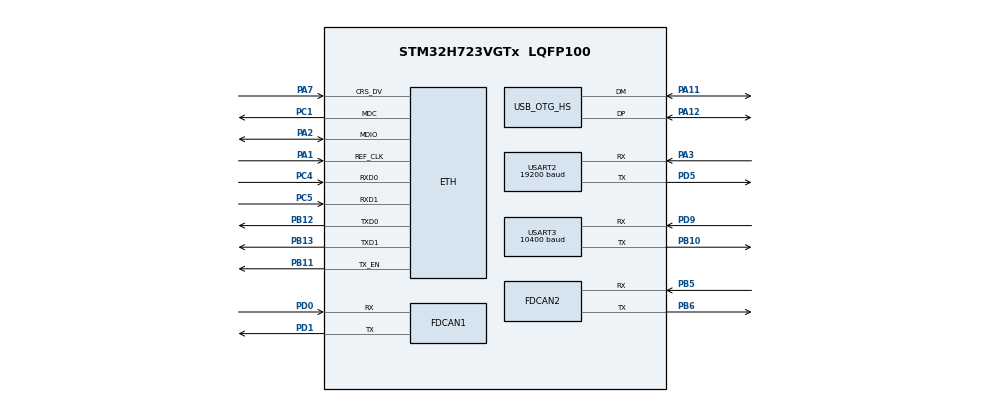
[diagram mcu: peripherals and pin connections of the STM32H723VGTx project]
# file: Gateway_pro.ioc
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CORTEX_M7.default_mode_Activation=1
Dma.Request0=USART2_RX
Dma.Request1=USART2_TX
Dma.USART2_RX.0.Direction=DMA_PERIPH_TO_MEMORY
Dma.USART2_RX.0.EventEnable=DISABLE
Dma.USART2_RX.0.FIFOMode=DMA_FIFOMODE_DISABLE
Dma.USART2_RX.0.Instance=DMA1_Stream0
Dma.USART2_RX.0.MemDataAlignment=DMA_MDATAALIGN_WORD
Dma.USART2_RX.0.MemInc=DMA_MINC_ENABLE
Dma.USART2_RX.0.Mode=DMA_CIRCULAR
Dma.USART2_RX.0.PeriphDataAlignment=DMA_PDATAALIGN_WORD
Dma.USART2_RX.0.PeriphInc=DMA_PINC_DISABLE
Dma.USART2_RX.0.Polarity=HAL_DMAMUX_REQ_GEN_RISING
Dma.USART2_RX.0.Priority=DMA_PRIORITY_LOW
Dma.USART2_RX.0.RequestNumber=1
Dma.USART2_RX.0.SignalID=NONE
Dma.USART2_RX.0.SyncEnable=DISABLE
Dma.USART2_RX.0.SyncPolarity=HAL_DMAMUX_SYNC_NO_EVENT
Dma.USART2_RX.0.SyncRequestNumber=1
Dma.USART2_RX.0.SyncSignalID=NONE
Dma.USART2_TX.1.Direction=DMA_MEMORY_TO_PERIPH
Dma.USART2_TX.1.EventEnable=DISABLE
Dma.USART2_TX.1.FIFOMode=DMA_FIFOMODE_DISABLE
Dma.USART2_TX.1.Instance=DMA1_Stream1
Dma.USART2_TX.1.MemDataAlignment=DMA_MDATAALIGN_WORD
Dma.USART2_TX.1.MemInc=DMA_MINC_ENABLE
Dma.USART2_TX.1.Mode=DMA_CIRCULAR
Dma.USART2_TX.1.PeriphDataAlignment=DMA_PDATAALIGN_WORD
Dma.USART2_TX.1.PeriphInc=DMA_PINC_DISABLE
Dma.USART2_TX.1.Polarity=HAL_DMAMUX_REQ_GEN_RISING
Dma.USART2_TX.1.Priority=DMA_PRIORITY_LOW
Dma.USART2_TX.1.RequestNumber=1
Dma.USART2_TX.1.SignalID=NONE
Dma.USART2_TX.1.SyncEnable=DISABLE
Dma.USART2_TX.1.SyncPolarity=HAL_DMAMUX_SYNC_NO_EVENT
Dma.USART2_TX.1.SyncRequestNumber=1
Dma.USART2_TX.1.SyncSignalID=NONE
ETH.MediaInterface=HAL_ETH_RMII_MODE
FDCAN1.CalculateBaudRateNominal=2604166
FDCAN1.CalculateTimeBitNominal=384
FDCAN1.CalculateTimeQuantumNominal=128.0
FDCAN2.CalculateBaudRateNominal=2604166
FDCAN2.CalculateTimeBitNominal=384
FDCAN2.CalculateTimeQuantumNominal=128.0
FREERTOS.Tasks01=defaultTask,24,128,StartDefaultTask,Default,NULL,Dynamic,NULL,NULL
FREERTOS.configENABLE_FPU=1
FREERTOS.configUSE_NEWLIB_REENTRANT=1
Mcu.Family=STM32H7
Mcu.Name=STM32H723VGTx
Mcu.Package=LQFP100
NVIC.DMA1_Stream0_IRQn=true\:5\:0\:false\:false\:true\:true\:false\:true\:true
NVIC.DMA1_Stream1_IRQn=true\:5\:0\:false\:false\:true\:true\:false\:true\:true
NVIC.OTG_HS_IRQn=true\:5\:0\:false\:false\:true\:true\:false\:true\:true
NVIC.PriorityGroup=NVIC_PRIORITYGROUP_4
NVIC.TIM6_DAC_IRQn=true\:15\:0\:false\:false\:true\:false\:false\:true\:true
NVIC.TimeBase=TIM6_DAC_IRQn
NVIC.TimeBaseIP=TIM6
PA1.Mode=RMII
PA1.Signal=ETH_REF_CLK
PA11.Mode=Device_Only_FS
PA11.Signal=USB_OTG_HS_DM
PA12.Mode=Device_Only_FS
PA12.Signal=USB_OTG_HS_DP
PA2.Mode=RMII
PA2.Signal=ETH_MDIO
PA3.Mode=Asynchronous
PA3.Signal=USART2_RX
PA7.Mode=RMII
PA7.Signal=ETH_CRS_DV
PB10.Mode=Asynchronous
PB10.Signal=USART3_TX
PB11.Mode=RMII
PB11.Signal=ETH_TX_EN
PB12.Mode=RMII
PB12.Signal=ETH_TXD0
PB13.Mode=RMII
PB13.Signal=ETH_TXD1
PB5.Mode=FDCAN_Activate
PB5.Signal=FDCAN2_RX
PB6.Mode=FDCAN_Activate
PB6.Signal=FDCAN2_TX
PC1.Mode=RMII
PC1.Signal=ETH_MDC
PC4.Mode=RMII
PC4.Signal=ETH_RXD0
PC5.Mode=RMII
PC5.Signal=ETH_RXD1
PD0.Mode=FDCAN_Activate
PD0.Signal=FDCAN1_RX
PD1.Mode=FDCAN_Activate
PD1.Signal=FDCAN1_TX
PD5.Mode=Asynchronous
PD5.Signal=USART2_TX
PD9.Mode=Asynchronous
PD9.Signal=USART3_RX
PH0-OSC_IN.Mode=HSE-External-Oscillator
PH0-OSC_IN.Signal=RCC_OSC_IN
PH1-OSC_OUT.Mode=HSE-External-Oscillator
PH1-OSC_OUT.Signal=RCC_OSC_OUT
ProjectManager.HeapSize=0x200
ProjectManager.StackSize=0x400
ProjectManager.TargetToolchain=STM32CubeIDE
RCC.ADCFreq_Value=50390625
RCC.APB1Freq_Value=125000000
RCC.APB2Freq_Value=125000000
RCC.APB3Freq_Value=125000000
RCC.APB4Freq_Value=125000000
RCC.CortexFreq_Value=500000000
RCC.D1PPRE=RCC_APB3_DIV2
RCC.D2PPRE1=RCC_APB1_DIV2
RCC.D2PPRE2=RCC_APB2_DIV2
RCC.D3PPRE=RCC_APB4_DIV2
RCC.DIVM1=2
RCC.DIVN1=40
RCC.DIVP1=1
RCC.DIVQ1=4
RCC.HCLKFreq_Value=250000000
RCC.HPRE=RCC_HCLK_DIV2
RCC.PLLFRACN=0
RCC.SYSCLKFreq_VALUE=500000000
RCC.SYSCLKSource=RCC_SYSCLKSOURCE_PLLCLK
RCC.USBFreq_Value=125000000
TIM2.Prescaler=249
USART2.BaudRate=19200
USART2.VirtualMode-Asynchronous=VM_ASYNC
USART3.BaudRate=10400
USART3.VirtualMode-Asynchronous=VM_ASYNC
USB_DEVICE.CLASS_NAME_HS=CDC
USB_DEVICE.VirtualMode=Cdc
USB_DEVICE.VirtualModeHS=Cdc_HS
USB_OTG_HS.VirtualMode-Device_Only_FS=Device_Only_FS
VP_FREERTOS_VS_CMSIS_V2.Mode=CMSIS_V2
VP_MEMORYMAP_VS_MEMORYMAP.Mode=CurAppReg
VP_RNG_VS_RNG.Mode=RNG_Activate
VP_SYS_VS_tim6.Mode=TIM6
VP_TIM2_VS_ClockSourceINT.Mode=Internal
VP_USB_DEVICE_VS_USB_DEVICE_CDC_HS.Mode=CDC_HS
board=custom

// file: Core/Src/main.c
/* USER CODE BEGIN Header */
/**
  ******************************************************************************
  * @file           : main.c
  * @brief          : Main program body
  ******************************************************************************
  * @attention
  *
  * Copyright (c) 2026 STMicroelectronics.
  * All rights reserved.
  *
  * This software is licensed under terms that can be found in the LICENSE file
  * in the root directory of this software component.
  * If no LICENSE file comes with this software, it is provided AS-IS.
  *
  ******************************************************************************
  */
/* USER CODE END Header */
#include "main.h"
#include "string.h"
#include "cmsis_os.h"
#include "usb_device.h"
#include "main_app.h"

#if defined ( __ICCARM__ ) /*!< IAR Compiler */
#pragma location=0x30000000
ETH_DMADescTypeDef  DMARxDscrTab[ETH_RX_DESC_CNT]; /* Ethernet Rx DMA Descriptors */
#pragma location=0x30000080
ETH_DMADescTypeDef  DMATxDscrTab[ETH_TX_DESC_CNT]; /* Ethernet Tx DMA Descriptors */

#elif defined ( __CC_ARM )  /* MDK ARM Compiler */

__attribute__((at(0x30000000))) ETH_DMADescTypeDef  DMARxDscrTab[ETH_RX_DESC_CNT]; /* Ethernet Rx DMA Descriptors */
__attribute__((at(0x30000080))) ETH_DMADescTypeDef  DMATxDscrTab[ETH_TX_DESC_CNT]; /* Ethernet Tx DMA Descriptors */

#elif defined ( __GNUC__ ) /* GNU Compiler */

ETH_DMADescTypeDef DMARxDscrTab[ETH_RX_DESC_CNT] __attribute__((section(".RxDescripSection"))); /* Ethernet Rx DMA Descriptors */
ETH_DMADescTypeDef DMATxDscrTab[ETH_TX_DESC_CNT] __attribute__((section(".TxDescripSection")));   /* Ethernet Tx DMA Descriptors */
#endif

ETH_TxPacketConfig TxConfig;

ETH_HandleTypeDef heth;

FDCAN_HandleTypeDef hfdcan1;
FDCAN_HandleTypeDef hfdcan2;

RNG_HandleTypeDef hrng;

TIM_HandleTypeDef htim2;

UART_HandleTypeDef huart2;
UART_HandleTypeDef huart3;
DMA_HandleTypeDef hdma_usart2_rx;
DMA_HandleTypeDef hdma_usart2_tx;

/* Definitions for defaultTask */
osThreadId_t defaultTaskHandle;
const osThreadAttr_t defaultTask_attributes = {
  .name = "defaultTask",
  .stack_size = 128 * 4,
  .priority = (osPriority_t) osPriorityNormal,
};

void SystemClock_Config(void);
static void MPU_Config(void);
static void MX_GPIO_Init(void);
static void MX_DMA_Init(void);
static void MX_FDCAN1_Init(void);
static void MX_FDCAN2_Init(void);
static void MX_RNG_Init(void);
static void MX_USART2_UART_Init(void);
static void MX_USART3_UART_Init(void);
static void MX_ETH_Init(void);
static void MX_TIM2_Init(void);
void StartDefaultTask(void *argument);

int main(void)
{

  /* MPU Configuration--------------------------------------------------------*/
  MPU_Config();

  /* MCU Configuration--------------------------------------------------------*/

  /* Reset of all peripherals, Initializes the Flash interface and the Systick. */
  HAL_Init();

  /* Configure the system clock */
  SystemClock_Config();

  /* Initialize all configured peripherals */
  MX_GPIO_Init();
  MX_DMA_Init();
  MX_FDCAN1_Init();
  MX_FDCAN2_Init();
  MX_RNG_Init();
  MX_USART2_UART_Init();
  MX_USART3_UART_Init();
  MX_ETH_Init();
  MX_TIM2_Init();
  /* USER CODE BEGIN 2 */
  HAL_TIM_Base_Start(&htim2);              // juste le compteur
  HAL_TIM_Base_Start_IT(&htim2);           // compteur avec interruption
  VCI_AppMain();
  /* USER CODE END 2 */

  /* Init scheduler */
  osKernelInitialize();

  /* Create the thread(s) */
  /* creation of defaultTask */
  defaultTaskHandle = osThreadNew(StartDefaultTask, NULL, &defaultTask_attributes);

  /* Start scheduler */
  osKernelStart();

  /* We should never get here as control is now taken by the scheduler */

  /* Infinite loop */
  while (1)
  {

  }
}

void SystemClock_Config(void)
{
  RCC_OscInitTypeDef RCC_OscInitStruct = {0};
  RCC_ClkInitTypeDef RCC_ClkInitStruct = {0};

  /** Supply configuration update enable
  */
  HAL_PWREx_ConfigSupply(PWR_LDO_SUPPLY);

  /** Configure the main internal regulator output voltage
  */
  __HAL_PWR_VOLTAGESCALING_CONFIG(PWR_REGULATOR_VOLTAGE_SCALE0);

  while(!__HAL_PWR_GET_FLAG(PWR_FLAG_VOSRDY)) {}

  /** Initializes the RCC Oscillators according to the specified parameters
  * in the RCC_OscInitTypeDef structure.
  */
  RCC_OscInitStruct.OscillatorType = RCC_OSCILLATORTYPE_HSI48|RCC_OSCILLATORTYPE_HSE;
  RCC_OscInitStruct.HSEState = RCC_HSE_ON;
  RCC_OscInitStruct.HSI48State = RCC_HSI48_ON;
  RCC_OscInitStruct.PLL.PLLState = RCC_PLL_ON;
  RCC_OscInitStruct.PLL.PLLSource = RCC_PLLSOURCE_HSE;
  RCC_OscInitStruct.PLL.PLLM = 2;
  RCC_OscInitStruct.PLL.PLLN = 40;
  RCC_OscInitStruct.PLL.PLLP = 1;
  RCC_OscInitStruct.PLL.PLLQ = 4;
  RCC_OscInitStruct.PLL.PLLR = 2;
  RCC_OscInitStruct.PLL.PLLRGE = RCC_PLL1VCIRANGE_3;
  RCC_OscInitStruct.PLL.PLLVCOSEL = RCC_PLL1VCOWIDE;
  RCC_OscInitStruct.PLL.PLLFRACN = 0;
  if (HAL_RCC_OscConfig(&RCC_OscInitStruct) != HAL_OK)
  {
    Error_Handler();
  }

  /** Initializes the CPU, AHB and APB buses clocks
  */
  RCC_ClkInitStruct.ClockType = RCC_CLOCKTYPE_HCLK|RCC_CLOCKTYPE_SYSCLK
                              |RCC_CLOCKTYPE_PCLK1|RCC_CLOCKTYPE_PCLK2
                              |RCC_CLOCKTYPE_D3PCLK1|RCC_CLOCKTYPE_D1PCLK1;
  RCC_ClkInitStruct.SYSCLKSource = RCC_SYSCLKSOURCE_PLLCLK;
  RCC_ClkInitStruct.SYSCLKDivider = RCC_SYSCLK_DIV1;
  RCC_ClkInitStruct.AHBCLKDivider = RCC_HCLK_DIV2;
  RCC_ClkInitStruct.APB3CLKDivider = RCC_APB3_DIV2;
  RCC_ClkInitStruct.APB1CLKDivider = RCC_APB1_DIV2;
  RCC_ClkInitStruct.APB2CLKDivider = RCC_APB2_DIV2;
  RCC_ClkInitStruct.APB4CLKDivider = RCC_APB4_DIV2;

  if (HAL_RCC_ClockConfig(&RCC_ClkInitStruct, FLASH_LATENCY_3) != HAL_OK)
  {
    Error_Handler();
  }
}

static void MX_ETH_Init(void)
{

   static uint8_t MACAddr[6];

  heth.Instance = ETH;
  MACAddr[0] = 0x00;
  MACAddr[1] = 0x80;
  MACAddr[2] = 0xE1;
  MACAddr[3] = 0x00;
  MACAddr[4] = 0x00;
  MACAddr[5] = 0x00;
  heth.Init.MACAddr = &MACAddr[0];
  heth.Init.MediaInterface = HAL_ETH_RMII_MODE;
  heth.Init.TxDesc = DMATxDscrTab;
  heth.Init.RxDesc = DMARxDscrTab;
  heth.Init.RxBuffLen = 1524;

  if (HAL_ETH_Init(&heth) != HAL_OK)
  {
    Error_Handler();
  }

  memset(&TxConfig, 0 , sizeof(ETH_TxPacketConfig));
  TxConfig.Attributes = ETH_TX_PACKETS_FEATURES_CSUM | ETH_TX_PACKETS_FEATURES_CRCPAD;
  TxConfig.ChecksumCtrl = ETH_CHECKSUM_IPHDR_PAYLOAD_INSERT_PHDR_CALC;
  TxConfig.CRCPadCtrl = ETH_CRC_PAD_INSERT;

}

static void MX_FDCAN1_Init(void)
{

  hfdcan1.Instance = FDCAN1;
  hfdcan1.Init.FrameFormat = FDCAN_FRAME_CLASSIC;
  hfdcan1.Init.Mode = FDCAN_MODE_NORMAL;
  hfdcan1.Init.AutoRetransmission = DISABLE;
  hfdcan1.Init.TransmitPause = DISABLE;
  hfdcan1.Init.ProtocolException = DISABLE;
  hfdcan1.Init.NominalPrescaler = 16;
  hfdcan1.Init.NominalSyncJumpWidth = 1;
  hfdcan1.Init.NominalTimeSeg1 = 1;
  hfdcan1.Init.NominalTimeSeg2 = 1;
  hfdcan1.Init.DataPrescaler = 1;
  hfdcan1.Init.DataSyncJumpWidth = 1;
  hfdcan1.Init.DataTimeSeg1 = 1;
  hfdcan1.Init.DataTimeSeg2 = 1;
  hfdcan1.Init.MessageRAMOffset = 0;
  hfdcan1.Init.StdFiltersNbr = 0;
  hfdcan1.Init.ExtFiltersNbr = 0;
  hfdcan1.Init.RxFifo0ElmtsNbr = 0;
  hfdcan1.Init.RxFifo0ElmtSize = FDCAN_DATA_BYTES_8;
  hfdcan1.Init.RxFifo1ElmtsNbr = 0;
  hfdcan1.Init.RxFifo1ElmtSize = FDCAN_DATA_BYTES_8;
  hfdcan1.Init.RxBuffersNbr = 0;
  hfdcan1.Init.RxBufferSize = FDCAN_DATA_BYTES_8;
  hfdcan1.Init.TxEventsNbr = 0;
  hfdcan1.Init.TxBuffersNbr = 0;
  hfdcan1.Init.TxFifoQueueElmtsNbr = 0;
  hfdcan1.Init.TxFifoQueueMode = FDCAN_TX_FIFO_OPERATION;
  hfdcan1.Init.TxElmtSize = FDCAN_DATA_BYTES_8;
  if (HAL_FDCAN_Init(&hfdcan1) != HAL_OK)
  {
    Error_Handler();
  }

}

static void MX_FDCAN2_Init(void)
{

  hfdcan2.Instance = FDCAN2;
  hfdcan2.Init.FrameFormat = FDCAN_FRAME_CLASSIC;
  hfdcan2.Init.Mode = FDCAN_MODE_NORMAL;
  hfdcan2.Init.AutoRetransmission = DISABLE;
  hfdcan2.Init.TransmitPause = DISABLE;
  hfdcan2.Init.ProtocolException = DISABLE;
  hfdcan2.Init.NominalPrescaler = 16;
  hfdcan2.Init.NominalSyncJumpWidth = 1;
  hfdcan2.Init.NominalTimeSeg1 = 1;
  hfdcan2.Init.NominalTimeSeg2 = 1;
  hfdcan2.Init.DataPrescaler = 1;
  hfdcan2.Init.DataSyncJumpWidth = 1;
  hfdcan2.Init.DataTimeSeg1 = 1;
  hfdcan2.Init.DataTimeSeg2 = 1;
  hfdcan2.Init.MessageRAMOffset = 0;
  hfdcan2.Init.StdFiltersNbr = 0;
  hfdcan2.Init.ExtFiltersNbr = 0;
  hfdcan2.Init.RxFifo0ElmtsNbr = 0;
  hfdcan2.Init.RxFifo0ElmtSize = FDCAN_DATA_BYTES_8;
  hfdcan2.Init.RxFifo1ElmtsNbr = 0;
  hfdcan2.Init.RxFifo1ElmtSize = FDCAN_DATA_BYTES_8;
  hfdcan2.Init.RxBuffersNbr = 0;
  hfdcan2.Init.RxBufferSize = FDCAN_DATA_BYTES_8;
  hfdcan2.Init.TxEventsNbr = 0;
  hfdcan2.Init.TxBuffersNbr = 0;
  hfdcan2.Init.TxFifoQueueElmtsNbr = 0;
  hfdcan2.Init.TxFifoQueueMode = FDCAN_TX_FIFO_OPERATION;
  hfdcan2.Init.TxElmtSize = FDCAN_DATA_BYTES_8;
  if (HAL_FDCAN_Init(&hfdcan2) != HAL_OK)
  {
    Error_Handler();
  }

}

static void MX_RNG_Init(void)
{

  hrng.Instance = RNG;
  hrng.Init.ClockErrorDetection = RNG_CED_ENABLE;
  if (HAL_RNG_Init(&hrng) != HAL_OK)
  {
    Error_Handler();
  }

}

static void MX_TIM2_Init(void)
{

  TIM_ClockConfigTypeDef sClockSourceConfig = {0};
  TIM_MasterConfigTypeDef sMasterConfig = {0};

  htim2.Instance = TIM2;
  htim2.Init.Prescaler = 249;
  htim2.Init.CounterMode = TIM_COUNTERMODE_UP;
  htim2.Init.Period = 4294967295;
  htim2.Init.ClockDivision = TIM_CLOCKDIVISION_DIV1;
  htim2.Init.AutoReloadPreload = TIM_AUTORELOAD_PRELOAD_DISABLE;
  if (HAL_TIM_Base_Init(&htim2) != HAL_OK)
  {
    Error_Handler();
  }
  sClockSourceConfig.ClockSource = TIM_CLOCKSOURCE_INTERNAL;
  if (HAL_TIM_ConfigClockSource(&htim2, &sClockSourceConfig) != HAL_OK)
  {
    Error_Handler();
  }
  sMasterConfig.MasterOutputTrigger = TIM_TRGO_RESET;
  sMasterConfig.MasterSlaveMode = TIM_MASTERSLAVEMODE_DISABLE;
  if (HAL_TIMEx_MasterConfigSynchronization(&htim2, &sMasterConfig) != HAL_OK)
  {
    Error_Handler();
  }

}

static void MX_USART2_UART_Init(void)
{

  huart2.Instance = USART2;
  huart2.Init.BaudRate = 19200;
  huart2.Init.WordLength = UART_WORDLENGTH_8B;
  huart2.Init.StopBits = UART_STOPBITS_1;
  huart2.Init.Parity = UART_PARITY_NONE;
  huart2.Init.Mode = UART_MODE_TX_RX;
  huart2.Init.HwFlowCtl = UART_HWCONTROL_NONE;
  huart2.Init.OverSampling = UART_OVERSAMPLING_16;
  huart2.Init.OneBitSampling = UART_ONE_BIT_SAMPLE_DISABLE;
  huart2.Init.ClockPrescaler = UART_PRESCALER_DIV1;
  huart2.AdvancedInit.AdvFeatureInit = UART_ADVFEATURE_NO_INIT;
  if (HAL_UART_Init(&huart2) != HAL_OK)
  {
    Error_Handler();
  }
  if (HAL_UARTEx_SetTxFifoThreshold(&huart2, UART_TXFIFO_THRESHOLD_1_8) != HAL_OK)
  {
    Error_Handler();
  }
  if (HAL_UARTEx_SetRxFifoThreshold(&huart2, UART_RXFIFO_THRESHOLD_1_8) != HAL_OK)
  {
    Error_Handler();
  }
  if (HAL_UARTEx_DisableFifoMode(&huart2) != HAL_OK)
  {
    Error_Handler();
  }

}

static void MX_USART3_UART_Init(void)
{

  huart3.Instance = USART3;
  huart3.Init.BaudRate = 10400;
  huart3.Init.WordLength = UART_WORDLENGTH_8B;
  huart3.Init.StopBits = UART_STOPBITS_1;
  huart3.Init.Parity = UART_PARITY_NONE;
  huart3.Init.Mode = UART_MODE_TX_RX;
  huart3.Init.HwFlowCtl = UART_HWCONTROL_NONE;
  huart3.Init.OverSampling = UART_OVERSAMPLING_16;
  huart3.Init.OneBitSampling = UART_ONE_BIT_SAMPLE_DISABLE;
  huart3.Init.ClockPrescaler = UART_PRESCALER_DIV1;
  huart3.AdvancedInit.AdvFeatureInit = UART_ADVFEATURE_NO_INIT;
  if (HAL_UART_Init(&huart3) != HAL_OK)
  {
    Error_Handler();
  }
  if (HAL_UARTEx_SetTxFifoThreshold(&huart3, UART_TXFIFO_THRESHOLD_1_8) != HAL_OK)
  {
    Error_Handler();
  }
  if (HAL_UARTEx_SetRxFifoThreshold(&huart3, UART_RXFIFO_THRESHOLD_1_8) != HAL_OK)
  {
    Error_Handler();
  }
  if (HAL_UARTEx_DisableFifoMode(&huart3) != HAL_OK)
  {
    Error_Handler();
  }

}

static void MX_DMA_Init(void)
{

  /* DMA controller clock enable */
  __HAL_RCC_DMA1_CLK_ENABLE();

  /* DMA interrupt init */
  /* DMA1_Stream0_IRQn interrupt configuration */
  HAL_NVIC_SetPriority(DMA1_Stream0_IRQn, 5, 0);
  HAL_NVIC_EnableIRQ(DMA1_Stream0_IRQn);
  /* DMA1_Stream1_IRQn interrupt configuration */
  HAL_NVIC_SetPriority(DMA1_Stream1_IRQn, 5, 0);
  HAL_NVIC_EnableIRQ(DMA1_Stream1_IRQn);

}

static void MX_GPIO_Init(void)
{

  /* GPIO Ports Clock Enable */
  __HAL_RCC_GPIOH_CLK_ENABLE();
  __HAL_RCC_GPIOC_CLK_ENABLE();
  __HAL_RCC_GPIOA_CLK_ENABLE();
  __HAL_RCC_GPIOB_CLK_ENABLE();
  __HAL_RCC_GPIOD_CLK_ENABLE();

}

void StartDefaultTask(void *argument)
{
  /* init code for USB_DEVICE */
  MX_USB_DEVICE_Init();
  for(;;)
  {
    osDelay(1);
  }
}

 /* MPU Configuration */

void MPU_Config(void)
{
  MPU_Region_InitTypeDef MPU_InitStruct = {0};

  /* Disables the MPU */
  HAL_MPU_Disable();

  /** Initializes and configures the Region and the memory to be protected
  */
  MPU_InitStruct.Enable = MPU_REGION_ENABLE;
  MPU_InitStruct.Number = MPU_REGION_NUMBER0;
  MPU_InitStruct.BaseAddress = 0x0;
  MPU_InitStruct.Size = MPU_REGION_SIZE_4GB;
  MPU_InitStruct.SubRegionDisable = 0x87;
  MPU_InitStruct.TypeExtField = MPU_TEX_LEVEL0;
  MPU_InitStruct.AccessPermission = MPU_REGION_NO_ACCESS;
  MPU_InitStruct.DisableExec = MPU_INSTRUCTION_ACCESS_DISABLE;
  MPU_InitStruct.IsShareable = MPU_ACCESS_SHAREABLE;
  MPU_InitStruct.IsCacheable = MPU_ACCESS_NOT_CACHEABLE;
  MPU_InitStruct.IsBufferable = MPU_ACCESS_NOT_BUFFERABLE;

  HAL_MPU_ConfigRegion(&MPU_InitStruct);
  /* Enables the MPU */
  HAL_MPU_Enable(MPU_PRIVILEGED_DEFAULT);

}

void HAL_TIM_PeriodElapsedCallback(TIM_HandleTypeDef *htim)
{
  if (htim->Instance == TIM6) {
    HAL_IncTick();
  }
}

void Error_Handler(void)
{
  __disable_irq();
  while (1)
  {
  }
}
